# PIC32CZ4010CA80176 register map
Vendor: Microchip Technology; Series: PIC32CZCA80; File version: 0
CPU: CM7 r1p1, selectable endian, MPU, FPU, double-precision FPU, I-cache, D-cache, ITCM, DTCM, 3 interrupt priority bits, 222 interrupts
Registers are 32-bit, read-write, reset 0x0 unless marked. A register's access mark holds for its fields unless they carry their own. Offsets are from the block's base; [hi:lo] are bit positions; lines under a group give offsets from that group; {n}, {i} and the like mark numbered series; 'fields as' and 'values as' point back to an identical list.

## ETH — Ethernet Controller
Base 0x45070000
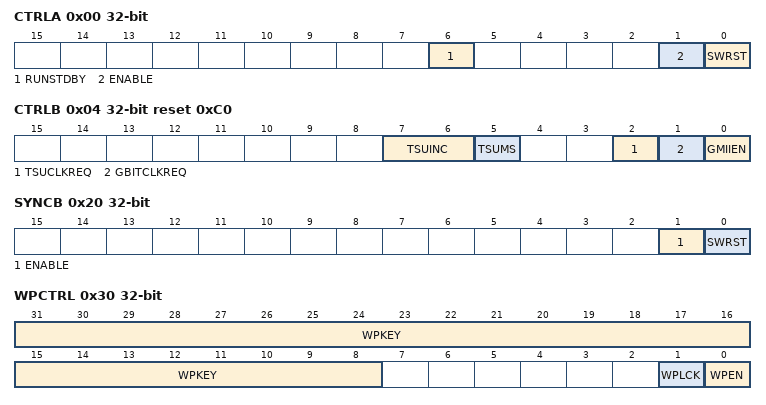
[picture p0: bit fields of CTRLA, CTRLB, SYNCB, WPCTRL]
0x00 CTRLA
  [6] RUNSTDBY — Run in standby mode
  [1] ENABLE — Macro Enable
  [0] SWRST — Software Reset Bit
0x04 CTRLB reset 0xC0
  [7:6] TSUINC — Timer Adjust Mode
  [5] TSUMS — Timer Adjust
  [2] TSUCLKREQ — TSU Clock Request
  [1] GBITCLKREQ — Gigabit clock request
  [0] GMIIEN — Select GMII/MII mode
0x0C EVCTRL — Event Control Register
  [0] CMPEO — Compare Event Out enable
0x20 SYNCB ro — Sync Busy Register
  [1] ENABLE — Enable Sync Busy
  [0] SWRST — Software Reset Sync Busy
0x30 WPCTRL — Write Protection Control Register
  [31:8] WPKEY — Write Protection Key
  [1] WPLCK — Write Lock Bit
  [0] WPEN — Write Protection Enable
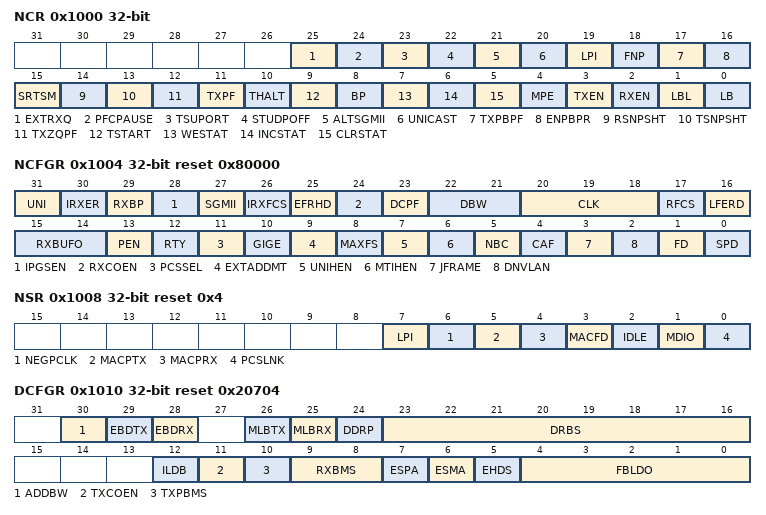
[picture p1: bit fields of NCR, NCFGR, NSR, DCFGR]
0x1000 NCR — Network Control Register
  [25] EXTRXQ — Exxternal RX Queue Enable
  [24] PFCPAUSE — PFC Pause Enable
  [23] TSUPORT — TSU Timer Port Enable
  [22] STUDPOFF — Store UDP Offset Enable
  [21] ALTSGMII — Alternative SGMII Mode Enable
  [20] UNICAST — Unicast PTP Farem Detection Enable
  [19] LPI — Low Power Idle Enable
  [18] FNP — Flush Next Packet
  [17] TXPBPF — Transmit PFC Priority-based Pause Frame
  [16] ENPBPR — Enable PFC Priority-based Pause Reception
  [15] SRTSM — Store Receive Time Stamp to Memory
  [14] RSNPSHT — Take Snapshot
  [13] TSNPSHT — Take Snapshot
  [12] TXZQPF — Transmit Zero Quantum Pause Frame
  [11] TXPF — Transmit Pause Frame
  [10] THALT — Transmit Halt
  [9] TSTART — Start Transmission
  [8] BP — Back pressure
  [7] WESTAT — Write Enable for Statistics Registers
  [6] INCSTAT — Increment Statistics Registers
  [5] CLRSTAT — Clear Statistics Registers
  [4] MPE — Management Port Enable
  [3] TXEN — Transmit Enable
  [2] RXEN — Receive Enable
  [1] LBL — Loop Back Local
  [0] LB — Loop Back
0x1004 NCFGR reset 0x80000 — Network Configuration Register
  [31] UNI — Uni-Direction Enable
  [30] IRXER — Ignore IPG GRXER
  [29] RXBP — Receive Bad Preamble
  [28] IPGSEN — IP Stretch Enable
  [27] SGMII — SGMII Mode Enable
  [26] IRXFCS — Ignore RX FCS
  [25] EFRHD — Enable Frames Received in Half Duplex
  [24] RXCOEN — Receive Checksum Offload Enable
  [23] DCPF — Disable Copy of Pause Frames
  [22:21] DBW — Data Bus Width
  [20:18] CLK — MDC CLock Division
  [17] RFCS — Remove FCS
  [16] LFERD — Length Field Error Frame Discard
  [15:14] RXBUFO — Receive Buffer Offset
  [13] PEN — Pause Enable
  [12] RTY — Retry Test
  [11] PCSSEL — PCS Select
  [10] GIGE — Gigabit mode Enable
  [9] EXTADDMT — External Address Match Enable
  [8] MAXFS — 1536 Maximum Frame Size
  [7] UNIHEN — Unicast Hash Enable
  [6] MTIHEN — Multicast Hash Enable
  [5] NBC — No Broadcast
  [4] CAF — Copy All Frames
  [3] JFRAME — Jumbo Frame Size
  [2] DNVLAN — Discard Non-VLAN FRAMES
  [1] FD — Full Duplex
  [0] SPD — Speed
0x1008 NSR ro reset 0x4 — Network Status Register
  [7] LPI — LPI Indication
  [6] NEGPCLK — PFC Priority Based Pause Negotiated
  [5] MACPTX — PCS Auto-Negotiation Pause Transmit Resolution
  [4] MACPRX — PCS Auto-Negotiation Pause Receive Resolution
  [3] MACFD — Auto-Negotiate Duplex Resolution
  [2] IDLE — PHY Management Logic Idle
  [1] MDIO — MDIO Input Status
  [0] PCSLNK — PCS Link State
0x100C UR — User Register
  [0] MII — MII Mode
0x1010 DCFGR reset 0x20704 — DMA Configuration Register
  [30] ADDBW — Address Bus Width
  [29] EBDTX — Extended TX BD Mode ENable
  [28] EBDRX — Extended RX BD Mode ENable
  [26] MLBTX — Force Max Length Burst Transmit
  [25] MLBRX — Force Max Length Burst Recieve
  [24] DDRP — DMA Discard Receive Packets
  [23:16] DRBS — DMA Receive Buffer Size
  [12] ILDB — Infinite Last Data Buffer
  [11] TXCOEN — Transmitter Checksum Generation Offload Enable
  [10] TXPBMS — Transmitter Packet Buffer Memory Size Select
  [9:8] RXBMS — Receiver Packet Buffer Memory Size Select
  [7] ESPA — Endian Swap Mode Enable for Packet Data Accesses
  [6] ESMA — Endian Swap Mode Enable for Management Descriptor Accesses
  [5] EHDS — Enable Header Data Splitting
  [4:0] FBLDO — Fixed Burst Length for DMA Data Operations:
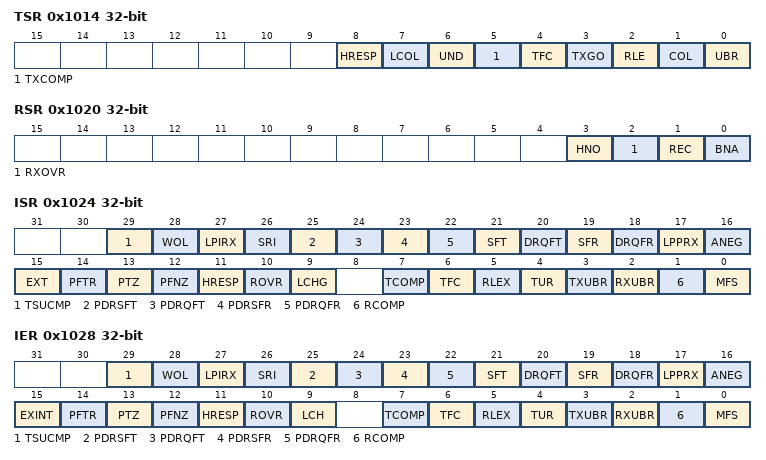
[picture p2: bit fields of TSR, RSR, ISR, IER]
0x1014 TSR — Transmit Status Register
  [8] HRESP — HRESP Not OK
  [7] LCOL — Late Colision Occured
  [6] UND — Transmit Underrun
  [5] TXCOMP — Transmit Complete
  [4] TFC — Transmit Frame Corruption Due to AHB Error
  [3] TXGO — Transmit Go
  [2] RLE — Retry Limit Exceeded
  [1] COL — Collision Occurred
  [0] UBR — Used Bit Read
0x1018 RBQB — Receive Buffer Queue Base Address
  [31:2] ADDR
0x101C TBQB — Transmit Buffer Queue Base Address
  [31:2] ADDR
0x1020 RSR — Receive Status Register
  [3] HNO — HRESP Not OK
  [2] RXOVR — Receive Overrun
  [1] REC — Frame Received
  [0] BNA — Buffer Not Available
0x1024 ISR — Interrupt Status Register
  [29] TSUCMP — Tsu timer comparison
  [28] WOL — Wake On LAN
  [27] LPIRX — Receive LPI Indication
  [26] SRI — TSU Seconds Register Increment
  [25] PDRSFT — PDelay Response Frame Transmitted
  [24] PDRQFT — PDelay Request Frame Transmitted
  [23] PDRSFR — PDelay Response Frame Received
  [22] PDRQFR — PDelay Request Frame Received
  [21] SFT — PTP Sync Frame Transmitted
  [20] DRQFT — PTP Delay Request Frame Transmitted
  [19] SFR — PTP Sync Frame Received
  [18] DRQFR — PTP Delay Request Frame Received
  [17] LPPRX — PCS Link Partner Page Recieved
  [16] ANEG — PCS Auto-Negotiation Complete
  [15] EXT — External
  [14] PFTR — Pause Frame Transmitted
  [13] PTZ — Pause Time Zero
  [12] PFNZ — Pause Frame with Non-zero Pause Quantum Received
  [11] HRESP — HRESP Not OK
  [10] ROVR — Receive Overrun
  [9] LCHG — Link Change
  [7] TCOMP — Transmit Complete
  [6] TFC — Transmit Frame Corruption Due to AHB Error
  [5] RLEX — Retry Limit Exceeded
  [4] TUR — Transmit Underrun
  [3] TXUBR — TX Used Bit Read
  [2] RXUBR — RX Used Bit Read
  [1] RCOMP — Receive Complete
  [0] MFS — Management Frame Sent
0x1028 IER wo — Interrupt Enable Register
  [29] TSUCMP — Tsu timer comparison
  [28] WOL — Wake On LAN
  [27] LPIRX — Receive LPI Indication
  [26] SRI — TSU Seconds Register Increment
  [25] PDRSFT — PDelay Response Frame Transmitted
  [24] PDRQFT — PDelay Request Frame Transmitted
  [23] PDRSFR — PDelay Response Frame Received
  [22] PDRQFR — PDelay Request Frame Received
  [21] SFT — PTP Sync Frame Transmitted
  [20] DRQFT — PTP Delay Request Frame Transmitted
  [19] SFR — PTP Sync Frame Received
  [18] DRQFR — PTP Delay Request Frame Received
  [17] LPPRX — PCS Link Partner Page Received
  [16] ANEG — PCS Auto-Negotiation Complete
  [15] EXINT — External Interrupt
  [14] PFTR — Pause Frame Transmitted
  [13] PTZ — Pause Time Zero
  [12] PFNZ — Pause Frame with Non-zero Pause Quantum Received
  [11] HRESP — HRESP Not OK
  [10] ROVR — Receive Overrun
  [9] LCH — Link Change
  [7] TCOMP — Transmit Complete
  [6] TFC — Transmit Frame Corruption Due to AHB Error
  [5] RLEX — Retry Limit Exceeded or Late Collision
  [4] TUR — Transmit Underrun
  [3] TXUBR — TX Used Bit Read
  [2] RXUBR — RX Used Bit Read
  [1] RCOMP — Receive Complete
  [0] MFS — Management Frame Sent
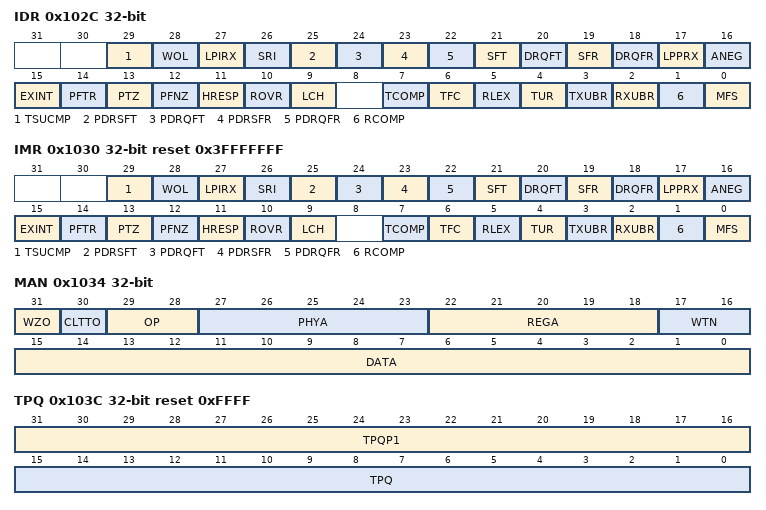
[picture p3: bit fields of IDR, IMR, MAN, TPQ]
0x102C IDR wo — Interrupt Disable Register
  fields as IER
0x1030 IMR ro reset 0x3FFFFFFF — Interrupt Mask Register
  fields as IER
0x1034 MAN — PHY Maintenance Register
  [31] WZO — Write ZERO
  [30] CLTTO — Clause 22 Operation
  [29:28] OP — Operation
  [27:23] PHYA — PHY Address
  [22:18] REGA — Register Address
  [17:16] WTN — Write Ten
  [15:0] DATA — PHY Data
0x1038 RPQ ro — Received Pause Quantum Register
  [15:0] RPQ — Received Pause Quantum
0x103C TPQ reset 0xFFFF — Transmit Pause Quantum Register
  [31:16] TPQP1 — Transmit Pause Quantum
  [15:0] TPQ — Transmit Pause Quantum
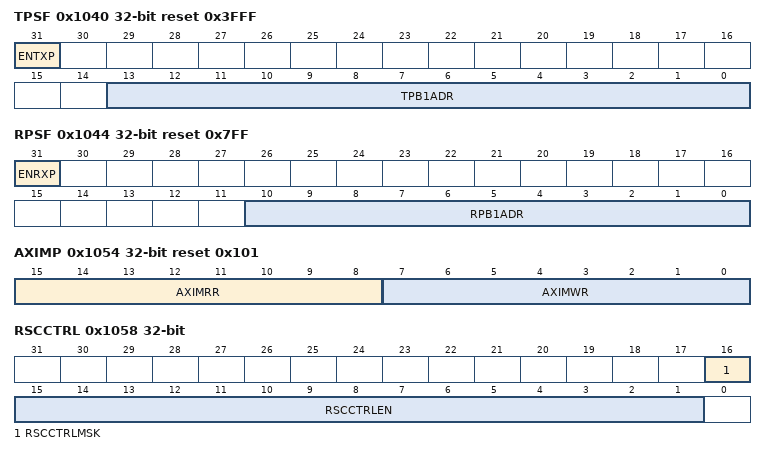
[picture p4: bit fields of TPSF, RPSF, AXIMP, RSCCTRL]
0x1040 TPSF reset 0x3FFF — TX partial store and forward Register
  [31] ENTXP — Enable TX partial store and forward operation
  [13:0] TPB1ADR — TX packet buffer address
0x1044 RPSF reset 0x7FF — RX partial store and forward Register
  [31] ENRXP — Enable RX partial store and forward operation
  [10:0] RPB1ADR — RX packet buffer address
0x1048 RJFML reset 0x2800 — RX Jumbo Frame Max Length Register
  [13:0] FML — Frame Max Length
0x104C EFIEN — External FIFO Interface Enable
  [0] EFIEN — Enable external fifo interface
0x1054 AXIMP reset 0x101 — AXI Max Pipeline
  [15:8] AXIMRR — AXI Max read requests
  [7:0] AXIMWR — AXI Max write requests
0x1058 RSCCTRL — Receive side coalescing on queues 1-15 Enable
  [16] RSCCTRLMSK — Mask the clearing of the rsc_en bit
  [15:1] RSCCTRLEN — Enables Receive Side Coalescing
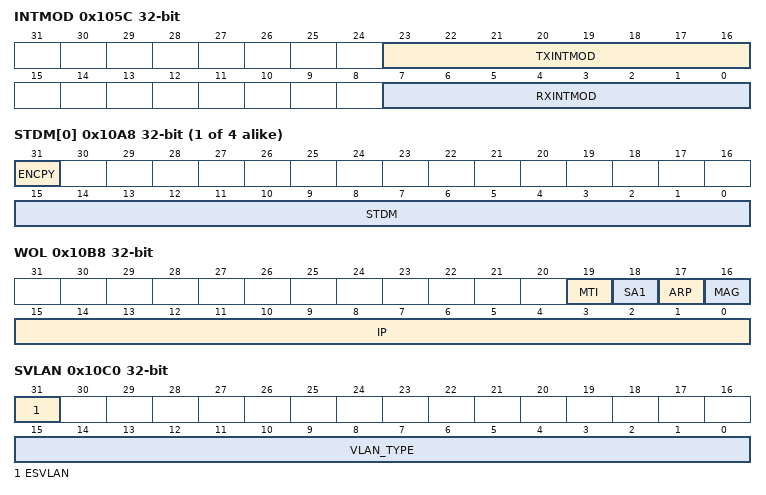
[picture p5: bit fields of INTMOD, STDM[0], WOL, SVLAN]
0x105C INTMOD — Interrupt Moderation
  [23:16] TXINTMOD — TX Interrupt Moderation
  [7:0] RXINTMOD — RX Interrupt Moderation
0x1060 SYSWT — Sys Wake Time
  [15:0] SYSWT
0x1080 HRB — Hash Register Bottom [31:0]
  [31:0] ADDR — Hash Address
0x1084 HRT — Hash Register Top [63:32]
  [31:0] ADDR — Hash Address
{0x1088+8i} SA[{i}] (i=0..3) group
  0x00 SAB — Specific Address Bottom [31:0] Register
    [31:0] ADDR — Specific Address 1
  0x04 SAT — Specific Address Top [47:32] Register
    [29:24] FLTBM — Filter byte mask
    [16] FLTT — Filter type
    [15:0] ADDR — Specific Address 1
{0x10A8+4i} STDM[{i}] (i=0..3) — Special Type ID Match N Register
  [31] ENCPY — Enable copying of type ID match N matched frames
  [15:0] STDM — Special Type ID Match N
0x10B8 WOL — Wake on LAN
  [19] MTI — WOL LAN multicast
  [18] SA1 — WOL specific address reg 1
  [17] ARP — LAN ARP req
  [16] MAG — Event enable
  [15:0] IP — IP address
0x10BC IPGS — IPG Stretch Register
  [15:0] FL — Frame Length
0x10C0 SVLAN — Stacked VLAN Register
  [31] ESVLAN — Enable Stacked VLAN Processing Mode
  [15:0] VLAN_TYPE — User Defined VLAN_TYPE Field
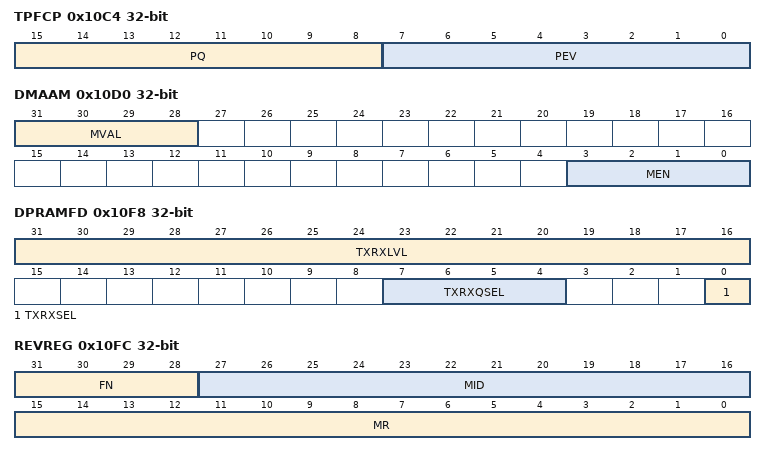
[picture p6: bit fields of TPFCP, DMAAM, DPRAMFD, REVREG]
0x10C4 TPFCP — Transmit PFC Pause Register
  [15:8] PQ — Pause Quantum
  [7:0] PEV — Priority Enable Vector
0x10C8 SAMB1 — Specific Address 1 Mask Bottom [31:0] Register
  [31:0] ADDR — Specific Address 1 Mask
0x10CC SAMT1 — Specific Address 1 Mask Top [47:32] Register
  [15:0] ADDR — Specific Address 1 Mask
0x10D0 DMAAM — Receive DMA Data Buffer Address Mask
  [31:28] MVAL — Mask Value
  [3:0] MEN — Mask Enable
0x10D4 PTPRXUC — PTP RX unicast IP destination address
  [31:0] ADD — Unicast IP destination address
0x10D8 PTPTXUC — PTP TX unicast IP destination address
  [31:0] ADD — Unicast IP destination address
0x10DC NSC — Tsu timer comparison nanoseconds Register
  [20:0] NANOSEC — 1588 Timer Nanosecond comparison value
0x10E0 SCL — Tsu timer second comparison Register
  [31:0] SEC — 1588 Timer Second comparison value
0x10E4 SCH — Tsu timer second comparison Register
  [15:0] SEC — 1588 Timer Second comparison value
0x10E8 EFTSH ro — PTP Event Frame Transmitted Seconds High Register
  [15:0] RUD — Register Update
0x10EC EFRSH ro — PTP Event Frame Received Seconds High Register
  [15:0] RUD — Register Update
0x10F0 PEFTSH ro — PTP Peer Event Frame Transmitted Seconds High Register
  [15:0] RUD — Register Update
0x10F4 PEFRSH ro — PTP Peer Event Frame Received Seconds High Register
  [15:0] RUD — Register Update
0x10F8 DPRAMFD — TX and RX packet buffer fill levels
  [31:16] TXRXLVL — TX/RX Buffer Fill Level
  [7:4] TXRXQSEL — TX/RX Fill Level Queue Select
  [0] TXRXSEL — TX/RX Fill Level Select
0x10FC REVREG ro — TX and RX packet buffer fill levels
  [31:28] FN — Fix Number
  [27:16] MID — Module Identification
  [15:0] MR — Module Revision
0x1100 OTLO — Octets Transmitted [31:0] Register
  [31:0] TXO — Transmitted Octets
0x1104 OTHI — Octets Transmitted [47:32] Register
  [15:0] TXO — Transmitted Octets
0x1108 FT — Frames Transmitted Register
  [31:0] FTX — Frames Transmitted without Error
0x110C BCFT — Broadcast Frames Transmitted Register
  [31:0] BFTX — Broadcast Frames Transmitted without Error
0x1110 MFT — Multicast Frames Transmitted Register
  [31:0] MFTX — Multicast Frames Transmitted without Error
0x1114 PFT — Pause Frames Transmitted Register
  [15:0] PFTX
0x1118 BFT64 — 64 Byte Frames Transmitted Register
  [31:0] NFTX — 64 Byte Frames Transmitted without Error
0x111C TBFT127 — 65 to 127 Byte Frames Transmitted Register
  [31:0] NFTX — 65 to 127 Byte Frames Transmitted without Error
0x1120 TBFT255 — 128 to 255 Byte Frames Transmitted Register
  [31:0] NFTX — 128 to 255 Byte Frames Transmitted without Error
0x1124 TBFT511 — 256 to 511 Byte Frames Transmitted Register
  [31:0] NFTX — 256 to 511 Byte Frames Transmitted without Error
0x1128 TBFT1023 — 512 to 1023 Byte Frames Transmitted Register
  [31:0] NFTX — 512 to 1023 Byte Frames Transmitted without Error
0x112C TBFT1518 — 1024 to 1518 Byte Frames Transmitted Register
  [31:0] NFTX — 1024 to 1518 Byte Frames Transmitted without Error
0x1130 GTBFT1518 — Greater Than 1518 Byte Frames Transmitted Register
  [31:0] NFTX — Greater than 1518 Byte Frames Transmitted without Error
0x1134 TUR — Transmit Underruns Register
  [9:0] TXUNR — Transmit Underruns
0x1138 SCF — Single Collision Frames Register
  [17:0] SCOL — Single Collision
0x113C MCF — Multiple Collision Frames Register
  [17:0] MCOL — Multiple Collision
0x1140 EC — Excessive Collisions Register
  [9:0] XCOL — Excessive Collisions
0x1144 LC — Late Collisions Register
  [9:0] LCOL — Late Collisions
0x1148 DTF — Deferred Transmission Frames Register
  [17:0] DEFT — Deferred Transmission
0x114C CSE — Carrier Sense Errors Register
  [9:0] CSR — Carrier Sense Error
0x1150 ORLO — Octets Received [31:0] Received
  [31:0] RXO — Received Octets
0x1154 ORHI — Octets Received [47:32] Received
  [15:0] RXO — Received Octets
0x1158 FR — Frames Received Register
  [31:0] FRX — Frames Received without Error
0x115C BCFR — Broadcast Frames Received Register
  [31:0] BFRX — Broadcast Frames Received without Error
0x1160 MFR — Multicast Frames Received Register
  [31:0] MFRX — Multicast Frames Received without Error
0x1164 PFR — Pause Frames Received Register
  [15:0] PFRX
0x1168 BFR64 — 64 Byte Frames Received Register
  [31:0] NFRX — 64 Byte Frames Received without Error
0x116C TBFR127 — 65 to 127 Byte Frames Received Register
  [31:0] NFRX — 65 to 127 Byte Frames Received without Error
0x1170 TBFR255 — 128 to 255 Byte Frames Received Register
  [31:0] NFRX — 128 to 255 Byte Frames Received without Error
0x1174 TBFR511 — 256 to 511Byte Frames Received Register
  [31:0] NFRX — 256 to 511 Byte Frames Received without Error
0x1178 TBFR1023 — 512 to 1023 Byte Frames Received Register
  [31:0] NFRX — 512 to 1023 Byte Frames Received without Error
0x117C TBFR1518 — 1024 to 1518 Byte Frames Received Register
  [31:0] NFRX — 1024 to 1518 Byte Frames Received without Error
0x1180 TMXBFR — 1519 to Maximum Byte Frames Received Register
  [31:0] NFRX — 1519 to Maximum Byte Frames Received without Error
0x1184 UFR — Undersize Frames Received Register
  [9:0] UFRX — Undersize Frames Received
0x1188 OFR — Oversize Frames Received Register
  [9:0] OFRX — Oversized Frames Received
0x118C JR — Jabbers Received Register
  [9:0] JRX — Jabbers Received
0x1190 FCSE — Frame Check Sequence Errors Register
  [9:0] FCKR — Frame Check Sequence Errors
0x1194 LFFE — Length Field Frame Errors Register
  [9:0] LFER — Length Field Frame Errors
0x1198 RSE — Receive Symbol Errors Register
  [9:0] RXSE — Receive Symbol Errors
0x119C AE — Alignment Errors Register
  [9:0] AER — Alignment Errors
0x11A0 RRE — Receive Resource Errors Register
  [17:0] RXRER — Receive Resource Errors
0x11A4 ROE — Receive Overrun Register
  [9:0] RXOVR — Receive Overruns
0x11A8 IHCE — IP Header Checksum Errors Register
  [7:0] HCKER — IP Header Checksum Errors
0x11AC TCE — TCP Checksum Errors Register
  [7:0] TCKER — TCP Checksum Errors
0x11B0 UCE — UDP Checksum Errors Register
  [7:0] UCKER — UDP Checksum Errors
0x11B4 AFP — UDP Checksum Errors Register
  [15:0] RDMAFP — Receive DMA Flushed Packets
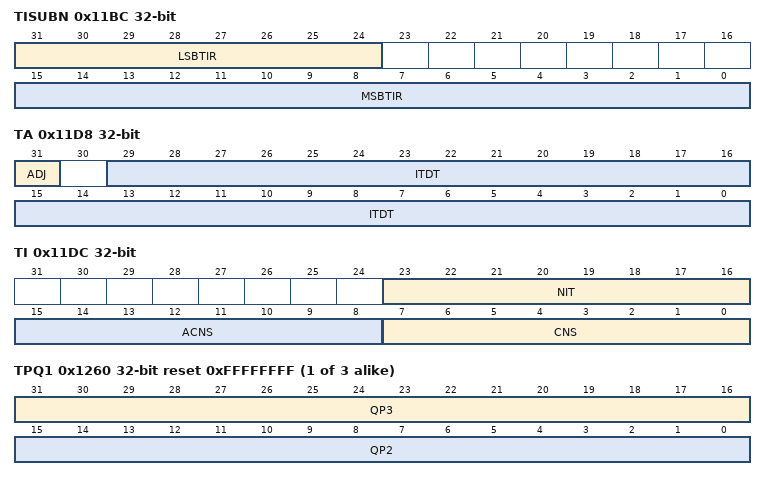
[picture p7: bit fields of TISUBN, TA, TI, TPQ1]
0x11BC TISUBN — 1588 Timer Increment [15:0] Sub-Nanoseconds Register
  [31:24] LSBTIR — LSB [7:0] of Timer Increment sub-ns value
  [15:0] MSBTIR — MSB [23:8] of Timer Increment sub-ns value
0x11C0 TSH — 1588 Timer Seconds Register 47:32
  [15:0] TMR — Timer Value MSB [47:32]
0x11C4 TSSSH ro — 1588 Timer Sync Strobe Seconds Register 47:32
  [15:0] VTS — 1588 Timer Sync Strobe Seconds
0x11C8 TSSSL ro — 1588 Timer Sync Strobe Seconds [31:0] Register
  [31:0] VTS — Value of Timer Seconds Register Capture
0x11CC TSSN ro — 1588 Timer Sync Strobe Nanoseconds Register
  [29:0] VTN — Value Timer Nanoseconds Register Capture
0x11D0 TSL — 1588 Timer Seconds [31:0] Register
  [31:0] TCS — Timer Count in Seconds
0x11D4 TN — 1588 Timer Nanoseconds Register
  [29:0] TNS — Timer Count in Nanoseconds
0x11D8 TA — 1588 Timer Adjust Register
  [31] ADJ — Adjust 1588 Timer
  [29:0] ITDT — Increment/Decrement
0x11DC TI — 1588 Timer Increment Register
  [23:16] NIT — Number of Increments
  [15:8] ACNS — Alternative Count Nanoseconds
  [7:0] CNS — Count Nanoseconds
0x11E0 EFTSL ro — PTP Event Frame Transmitted Seconds Low Register
  [31:0] RUD — Register Update
0x11E4 EFTN ro — PTP Event Frame Transmitted Nanoseconds
  [29:0] RUD — Register Update
0x11E8 EFRSL ro — PTP Event Frame Received Seconds Low Register
  [31:0] RUD — Register Update
0x11EC EFRN ro — PTP Event Frame Received Nanoseconds
  [29:0] RUD — Register Update
0x11F0 PEFTSL ro — PTP Peer Event Frame Transmitted Seconds Low Register
  [31:0] RUD — Register Update
0x11F4 PEFTN ro — PTP Peer Event Frame Transmitted Nanoseconds
  [29:0] RUD — Register Update
0x11F8 PEFRSL ro — PTP Peer Event Frame Received Seconds Low Register
  [31:0] RUD — Register Update
0x11FC PEFRN ro — PTP Peer Event Frame Received Nanoseconds
  [29:0] RUD — Register Update
{0x125C+4i} TPQ{i} reset 0xFFFFFFFF (i=1..3) — Transmit Pause Quantum Register {i}
  [31:16] QP{2i+1} — Transmit pause quantum priority {2i+1}
  [15:0] QP{2i} — Transmit pause quantum priority {2i}
0x1270 RLPITR ro — Receive LPI transition Register
  [15:0] RLPITR — Count number of times transition from rx normal idle to low power idle
0x1274 RLPITI ro — Receive LPI Time Register
  [23:0] RLPITI — Increment once over 16 ahb clock when LPI indication bit 20 is set in rx mode
0x1278 TLPITR ro — Receive LPI transition Register
  [15:0] TLPITR — Count number of times enable LPI tx bit 20 goes from low to high
0x127C TLPITI ro — Receive LPI Time Register
  [23:0] TLPITI — Increment once over 16 ahb clock when LPI indication bit 20 is set in tx mode
{0x1280+4i} DSNCFGDBG[{i}] (i=0..9) ro — Design Configuration Debug
  [31:0] DSNCFGDBG
{0x1300+8i} SAU[{i}] (i=0..31) group
  0x00 SAB — Specific Address Bottom [31:0] Register
    [31:0] ADDR — Specific Address 1
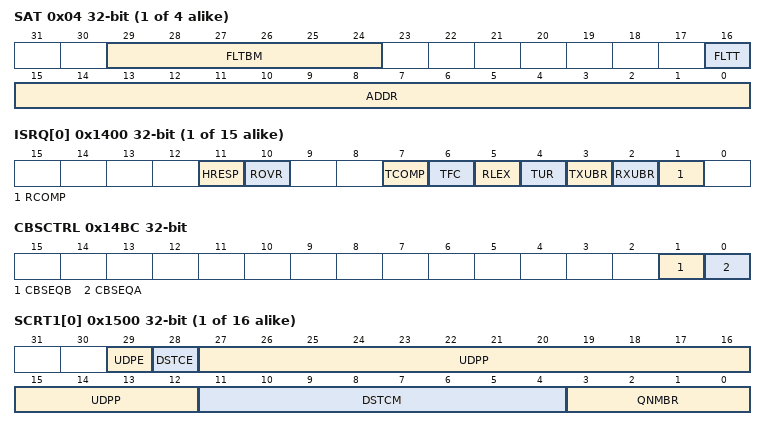
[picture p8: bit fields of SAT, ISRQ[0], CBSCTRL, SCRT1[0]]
  0x04 SAT — Specific Address Top [47:32] Register
    fields as SA[0].SAT
{0x1400+4i} ISRQ[{i}] (i=0..14) — Interrupt Status Register Queues
  [11] HRESP — HRESP Not OK
  [10] ROVR — Receive Overrun
  [7] TCOMP — Transmit Complete
  [6] TFC — Transmit Frame Corruption Due to AHB Error
  [5] RLEX — Retry Limit Exceeded
  [4] TUR — Transmit Underrun
  [3] TXUBR — TX Used Bit Read
  [2] RXUBR — RX Used Bit Read
  [1] RCOMP — Receive Complete
{0x1440+4i} TBPQB[{i}] (i=0..14) — Transmit Priority Queue Buffer Base Address
{0x1480+4i} RBPQB[{i}] (i=0..6) — Receive Priority Queue Buffer Base Address
{0x14A0+4i} RBQSZ[{i}] (i=0..6) reset 0x2 — Receive Priority Queue Buffer Size
  [7:0] RXBUFSZ — DMA Receive Buffer Size
0x14BC CBSCTRL — CBS Control Register
  [1] CBSEQB — Enable Credit-Based shaping on the 2nd highest priority queue (queue B)
  [0] CBSEQA — Enable Credit-Based shaping on the highest priority queue (queue A)
0x14C0 CBSISQA — IdleSlope value for queue A
  [31:0] ISA
0x14C4 CBSISQB — IdleSlope value for queue B
  [31:0] ISA — IdleSlope value for queue A
0x14C8 UTXQBA — Upper 32 bits of transmit buffer descriptor queue base address
0x14CC TXBDCTRL — TX BD control register
  [5:4] TXBDTSM — TX Descriptor Timestamp Insertion mode
0x14D0 RXBDCTRL — RX BD control register
  [5:4] RXBDTSM — RX Descriptor Timestamp Insertion mode
0x14D4 URXQBA — Upper 32 bits of receive buffer descriptor queue base address
{0x1500+4i} SCRT1[{i}] (i=0..15) — Screening Type 1 Register N
  [29] UDPE — UDP Port Match Enable
  [28] DSTCE — DS/TC Enable
  [27:12] UDPP — UDP Port Match
  [11:4] DSTCM — DS/TC Match
  [3:0] QNMBR — Queue Number
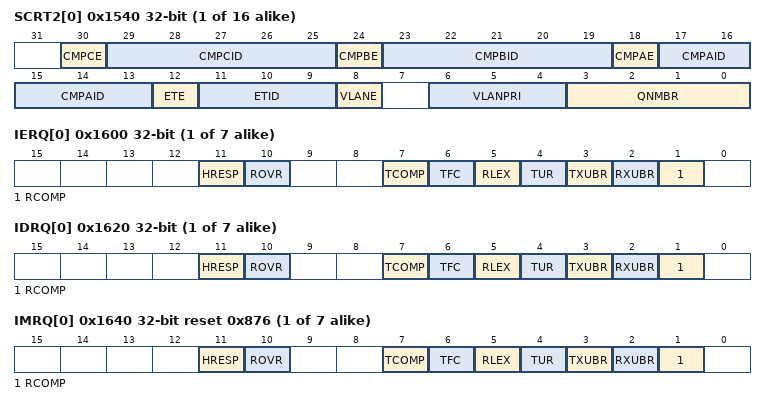
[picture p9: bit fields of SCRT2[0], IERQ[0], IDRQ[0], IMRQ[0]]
{0x1540+4i} SCRT2[{i}] (i=0..15) — Screening Type 2 Register
  [30] CMPCE — Compare C Enable
  [29:25] CMPCID — Compare C Index
  [24] CMPBE — Compare B Enable
  [23:19] CMPBID — Compare B Index
  [18] CMPAE — Compare A Enable
  [17:13] CMPAID — Compare A Index
  [12] ETE — EtherType Enable
  [11:9] ETID — EtherType Index
  [8] VLANE — VLAN Enable
  [6:4] VLANPRI — VLAN Priority
  [3:0] QNMBR — Queue Number
{0x15C0+4i} RXQPTR[{i}] (i=0..7) — Receive buffer queue base address
  [31:2] DMARXQPTR
{0x15E0+4i} DMARXQS[{i}] (i=0..7) — Receive Buffer Queue Size
  [7:0] DMARXQS
{0x1600+4i} IERQ[{i}] (i=0..6) — Interrupt Enable Queue N
  fields as ISRQ[0]
{0x1620+4i} IDRQ[{i}] (i=0..6) — Interrupt Disable Queue N
  fields as ISRQ[0]
{0x1640+4i} IMRQ[{i}] (i=0..6) reset 0x876 — Interrupt Mask Queue Register
  fields as ISRQ[0]
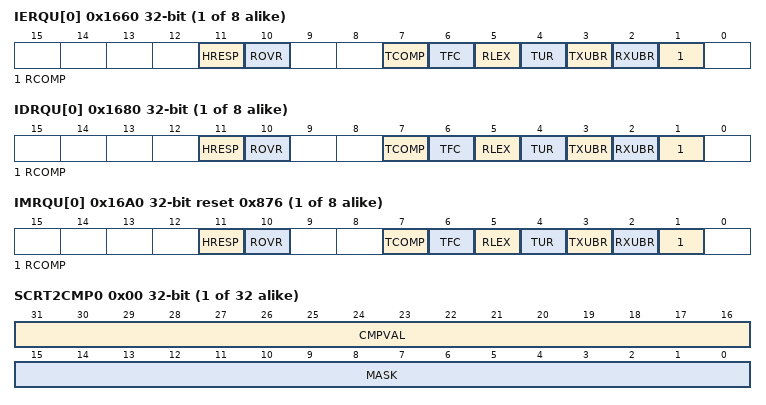
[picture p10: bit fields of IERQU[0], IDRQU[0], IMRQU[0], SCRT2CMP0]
{0x1660+4i} IERQU[{i}] (i=0..7) — Interrupt Enable Queue N (upper)
  fields as ISRQ[0]
{0x1680+4i} IDRQU[{i}] (i=0..7) — Interrupt Disable Queue N (upper)
  fields as ISRQ[0]
{0x16A0+4i} IMRQU[{i}] (i=0..7) reset 0x876 — Interrupt Mask Queue N (upper)
  fields as ISRQ[0]
{0x16E0+4i} SCRT2ET[{i}] (i=0..7) — Screening Type 2 EtherType Register
  [15:0] CMPVAL — Ethertype compare value
{0x1700+8i} SCRT2CMP[{i}] (i=0..31) group
  0x00 SCRT2CMP0 — Screening Type 2 Compare Registers Word 0
    [31:16] CMPVAL — 2Byte Compare Value
    [15:0] MASK — 2Byte Mask/Compare Value
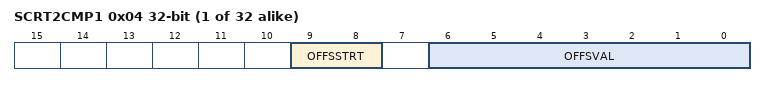
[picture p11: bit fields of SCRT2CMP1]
  0x04 SCRT2CMP1 — Screening Type 2 Compare Registers Word 1
    [9:8] OFFSSTRT — Offset Start
    [6:0] OFFSVAL — Offset Value

## Notices in the file
Copyright (c) 2023 Microchip Technology Inc.
SPDX-License-Identifier: Apache-2.0
Licensed under the Apache License, Version 2.0 (the "License");
you may not use this file except in compliance with the License.
You may obtain a copy of the License at
http://www.apache.org/licenses/LICENSE-2.0
Unless required by applicable law or agreed to in writing, software
distributed under the License is distributed on an "AS IS" BASIS,
WITHOUT WARRANTIES OR CONDITIONS OF ANY KIND, either express or implied.
See the License for the specific language governing permissions and
limitations under the License.
